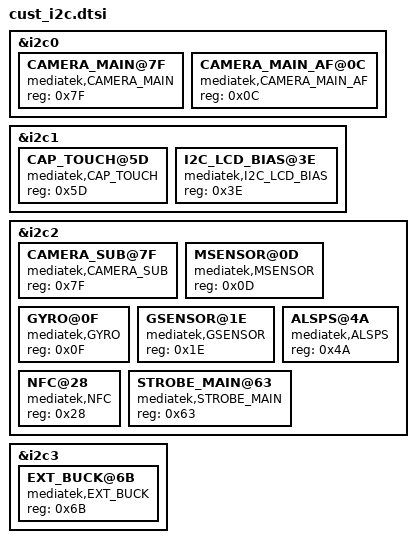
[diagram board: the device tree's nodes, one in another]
/*
 * Generated by MTK SP Drv_CodeGen Version 03.13.6  for MT6735M. Copyright MediaTek Inc. (C) 2013.
 * Wed Mar  1 20:58:32 2017
 * Do Not Modify the File.
 */

/*************************
 * I2C DTSI File
*************************/

&i2c0 {
	CAMERA_MAIN@7F {
		compatible = "mediatek,CAMERA_MAIN";
		reg = <0x7F>;
	};

	CAMERA_MAIN_AF@0C {
		compatible = "mediatek,CAMERA_MAIN_AF";
		reg = <0x0C>;
	};

};

&i2c1 {
	CAP_TOUCH@5D {
		compatible = "mediatek,CAP_TOUCH";
		reg = <0x5D>;
	};

	I2C_LCD_BIAS@3E {
		compatible = "mediatek,I2C_LCD_BIAS";
		reg = <0x3E>;
	};

};

&i2c2 {
	CAMERA_SUB@7F {
		compatible = "mediatek,CAMERA_SUB";
		reg = <0x7F>;
	};

	MSENSOR@0D {
		compatible = "mediatek,MSENSOR";
		reg = <0x0D>;
	};

	GYRO@0F {
		compatible = "mediatek,GYRO";
		reg = <0x0F>;
	};

	GSENSOR@1E {
		compatible = "mediatek,GSENSOR";
		reg = <0x1E>;
	};

	ALSPS@4A {
		compatible = "mediatek,ALSPS";
		reg = <0x4A>;
	};

	NFC@28 {
		compatible = "mediatek,NFC";
		reg = <0x28>;
	};

	STROBE_MAIN@63 {
		compatible = "mediatek,STROBE_MAIN";
		reg = <0x63>;
	};

};

&i2c3 {
	EXT_BUCK@6B {
		compatible = "mediatek,EXT_BUCK";
		reg = <0x6B>;
	};

};

